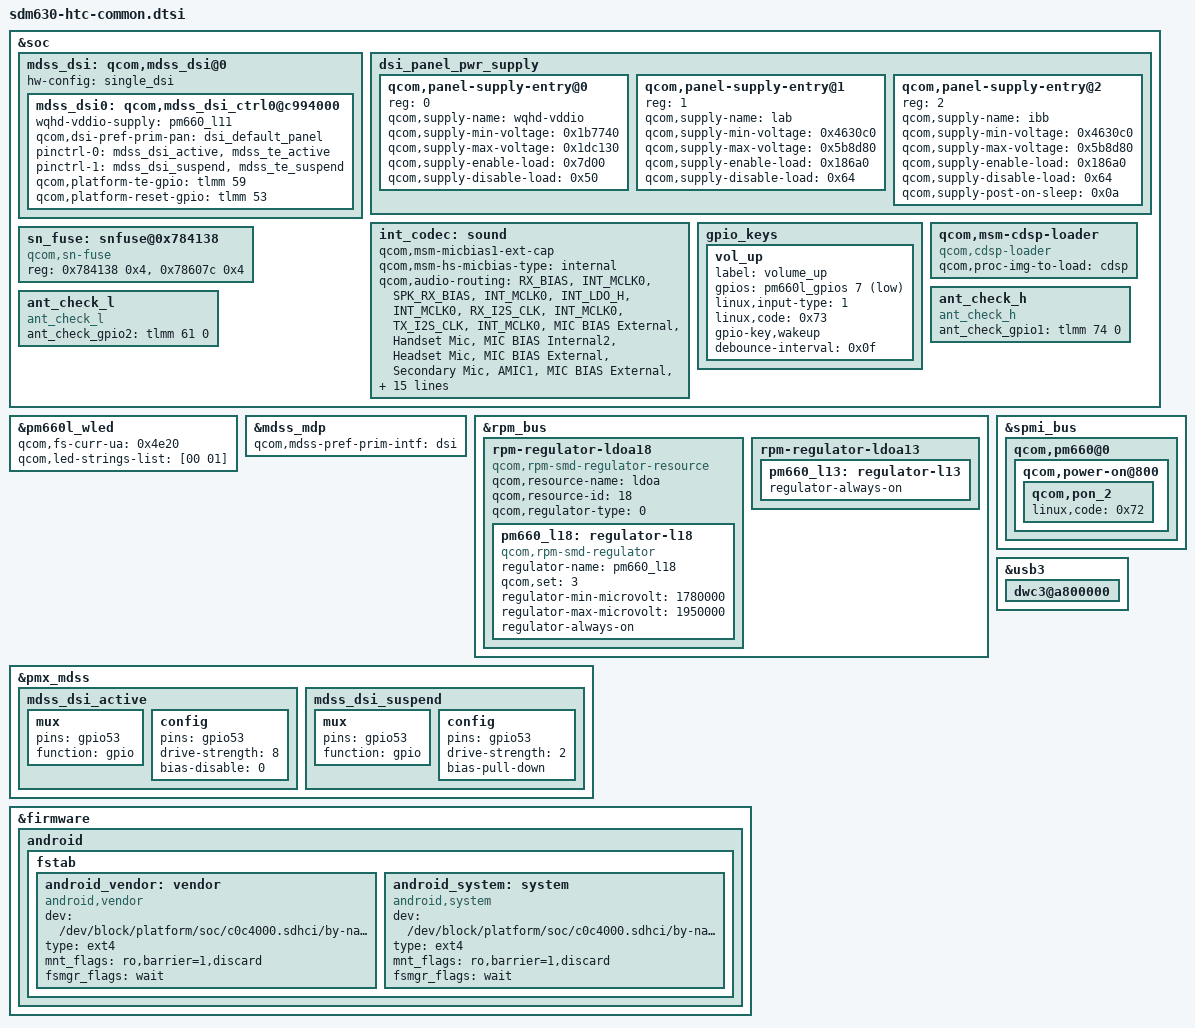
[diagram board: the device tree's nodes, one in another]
/* Copyright (c) 2017, The Linux Foundation. All rights reserved.
*
* This program is free software; you can redistribute it and/or modify
* it under the terms of the GNU General Public License version 2 and
* only version 2 as published by the Free Software Foundation.
*
* This program is distributed in the hope that it will be useful,
* but WITHOUT ANY WARRANTY; without even the implied warranty of
* MERCHANTABILITY or FITNESS FOR A PARTICULAR PURPOSE.  See the
* GNU General Public License for more details.
*/

#include "charger-htc-common.dtsi"
#include <dt-bindings/gpio/gpio.h>

&soc {
	mdss_dsi: qcom,mdss_dsi@0 {
		mdss_dsi0: qcom,mdss_dsi_ctrl0@c994000 {
			wqhd-vddio-supply = <&pm660_l11>;
		};
	};
	
	dsi_panel_pwr_supply: dsi_panel_pwr_supply {
		#address-cells = <1>;
		#size-cells = <0>;
		
		qcom,panel-supply-entry@0 {
			reg = <0>;
			qcom,supply-name = "wqhd-vddio";
			qcom,supply-min-voltage = <0x1b7740>;
			qcom,supply-max-voltage = <0x1dc130>;
			qcom,supply-enable-load = <0x7d00>;
			qcom,supply-disable-load = <0x50>;
		};
		
		qcom,panel-supply-entry@1 {
			reg = <1>;
			qcom,supply-name = "lab";
			qcom,supply-min-voltage = <0x4630c0>;
			qcom,supply-max-voltage = <0x5b8d80>;
			qcom,supply-enable-load = <0x186a0>;
			qcom,supply-disable-load = <0x64>;
		};
		
		qcom,panel-supply-entry@2 {
			reg = <2>;
			qcom,supply-name = "ibb";
			qcom,supply-min-voltage = <0x4630c0>;
			qcom,supply-max-voltage = <0x5b8d80>;
			qcom,supply-enable-load = <0x186a0>;
			qcom,supply-disable-load = <0x64>;
			qcom,supply-post-on-sleep = <0x0a>;
		};
	};
	
	int_codec: sound {
		qcom,msm-micbias1-ext-cap;
		qcom,msm-hs-micbias-type = "internal";
		qcom,audio-routing =
		"RX_BIAS", "INT_MCLK0",
		"SPK_RX_BIAS", "INT_MCLK0",
		"INT_LDO_H", "INT_MCLK0",
		"RX_I2S_CLK", "INT_MCLK0",
		"TX_I2S_CLK", "INT_MCLK0",
		"MIC BIAS External", "Handset Mic",
		"MIC BIAS Internal2", "Headset Mic",
		"MIC BIAS External", "Secondary Mic",
		"AMIC1", "MIC BIAS External",
		"AMIC2", "MIC BIAS Internal2",
		"AMIC3", "MIC BIAS External",
		"DMIC1", "MIC BIAS External",
		"MIC BIAS External", "Digital Mic1",
		"DMIC2", "MIC BIAS External",
		"MIC BIAS External", "Digital Mic2",
		"DMIC3", "MIC BIAS External",
		"MIC BIAS External", "Digital Mic3",
		"DMIC4", "MIC BIAS External",
		"MIC BIAS External", "Digital Mic4",
		"SpkrLeft IN", "SPK1 OUT",
		"SpkrRight IN", "SPK2 OUT",
		"PDM_IN_RX1", "PDM_OUT_RX1",
		"PDM_IN_RX2", "PDM_OUT_RX2",
		"PDM_IN_RX3", "PDM_OUT_RX3",
		"ADC1_IN", "ADC1_OUT",
		"ADC2_IN", "ADC2_OUT",
		"ADC3_IN", "ADC3_OUT";
		
		qcom,wsa-max-devs = <1>;
		qcom,wsa-aux-dev-prefix = "SpkrLeft", "SpkrLeft",
		"SpkrLeft", "SpkrLeft";
	};
	
	gpio_keys {
		/delete-node/vol_down;
		vol_up {
			label = "volume_up";
			gpios = <&pm660l_gpios 7 0x1>;
			linux,input-type = <1>;
			linux,code = <0x73>;
			gpio-key,wakeup;
			debounce-interval = <0x0f>;
		};
	};

	qcom,msm-cdsp-loader {
		compatible = "qcom,cdsp-loader";
		qcom,proc-img-to-load = "cdsp";
	};

	sn_fuse: snfuse@0x784138 {
		compatible = "qcom,sn-fuse";
		reg = <0x784138 0x4>, <0x78607c 0x4>;
		reg-names = "sn-base", "fuse-state";
	};

	/delete-node/ qcom,qbt1000;
	
	ant_check_h {
		compatible = "ant_check_h";
		ant_check_gpio1 = <&tlmm 74 0>;
	};

	ant_check_l {
		compatible = "ant_check_l";
		ant_check_gpio2 = <&tlmm 61 0>;
	};
};

&pm660l_wled {
	qcom,fs-curr-ua = <0x4e20>;
	qcom,led-strings-list = [00 01];
};

&mdss_mdp {
	qcom,mdss-pref-prim-intf = "dsi";
};

&mdss_dsi {
	hw-config = "single_dsi";
};

&rpm_bus {
	rpm-regulator-ldoa18 {
		compatible = "qcom,rpm-smd-regulator-resource";
		qcom,resource-name = "ldoa";
		qcom,resource-id = <18>;
		qcom,regulator-type = <0>;
		status = "okay";
		pm660_l18: regulator-l18 {
			compatible = "qcom,rpm-smd-regulator";
			regulator-name = "pm660_l18";
			qcom,set = <3>;
			regulator-min-microvolt = <1780000>;
			regulator-max-microvolt = <1950000>;
			status = "okay";
			regulator-always-on;
		};
	};

	rpm-regulator-ldoa13 {
		pm660_l13: regulator-l13 {
			regulator-always-on;
		};
	};
};

&pmx_mdss{
	mdss_dsi_active: mdss_dsi_active {
		mux {
			pins = "gpio53";
			function = "gpio";
		};
		
		config {
			pins = "gpio53";
			drive-strength = <8>; /* 8 mA */
			bias-disable = <0>; /* no pull */
		};
	};
	mdss_dsi_suspend: mdss_dsi_suspend {
		mux {
			pins = "gpio53";
			function = "gpio";
		};
		
		config {
			pins = "gpio53";
			drive-strength = <2>; /* 2 mA */
			bias-pull-down; /* pull down */
		};
	};
};


&spmi_bus {
	qcom,pm660@0 {
		qcom,power-on@800 {
			qcom,pon_2 {
				linux,code = <0x72>;
			};
		};
	};
};

&mdss_dsi0 {
	qcom,dsi-pref-prim-pan = <&dsi_default_panel>;
	pinctrl-names = "mdss_default", "mdss_sleep";
	pinctrl-0 = <&mdss_dsi_active &mdss_te_active>;
	pinctrl-1 = <&mdss_dsi_suspend &mdss_te_suspend>;
	qcom,platform-te-gpio = <&tlmm 59 0>;
	qcom,platform-reset-gpio = <&tlmm 53 0>;
};

&usb3 {
	dwc3@a800000 {
	};
};

&firmware {
	android {
		fstab {
			android_vendor: vendor {
				compatible = "android,vendor";
				dev = "/dev/block/platform/soc/c0c4000.sdhci/by-name/vendor";
				type = "ext4";
				mnt_flags = "ro,barrier=1,discard";
				fsmgr_flags = "wait";
				status = "ok";
			};
			android_system: system {
				compatible = "android,system";
				dev = "/dev/block/platform/soc/c0c4000.sdhci/by-name/system";
				type = "ext4";
				mnt_flags = "ro,barrier=1,discard";
				fsmgr_flags = "wait";
				status = "ok";
			};
		};
	};
};
